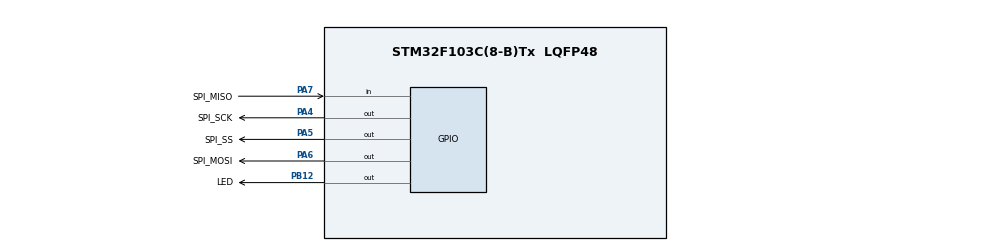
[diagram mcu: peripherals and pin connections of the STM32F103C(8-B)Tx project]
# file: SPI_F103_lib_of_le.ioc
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Mcu.Family=STM32F1
Mcu.Name=STM32F103C(8-B)Tx
Mcu.Package=LQFP48
NVIC.PriorityGroup=NVIC_PRIORITYGROUP_4
PA13.Mode=Serial_Wire
PA13.Signal=SYS_JTMS-SWDIO
PA14.Mode=Serial_Wire
PA14.Signal=SYS_JTCK-SWCLK
PA4.GPIO_Label=SPI_SCK
PA4.GPIO_Speed=GPIO_SPEED_FREQ_HIGH
PA4.Signal=GPIO_Output
PA5.GPIO_Label=SPI_SS
PA5.GPIO_Speed=GPIO_SPEED_FREQ_HIGH
PA5.Signal=GPIO_Output
PA6.GPIO_Label=SPI_MOSI
PA6.GPIO_Speed=GPIO_SPEED_FREQ_HIGH
PA6.Signal=GPIO_Output
PA7.GPIO_Label=SPI_MISO
PA7.Signal=GPIO_Input
PB12.GPIO_Label=LED
PB12.Signal=GPIO_Output
PD0-OSC_IN.Mode=HSE-External-Oscillator
PD0-OSC_IN.Signal=RCC_OSC_IN
PD1-OSC_OUT.Mode=HSE-External-Oscillator
PD1-OSC_OUT.Signal=RCC_OSC_OUT
ProjectManager.HeapSize=0x200
ProjectManager.StackSize=0x400
ProjectManager.TargetToolchain=STM32CubeIDE
RCC.APB1Freq_Value=8000000
RCC.APB2Freq_Value=8000000
RCC.SYSCLKSource=RCC_SYSCLKSOURCE_HSE
board=custom

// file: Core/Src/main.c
/* USER CODE BEGIN Header */
/**
  ******************************************************************************
  * @file           : main.c
  * @brief          : Main program body
  ******************************************************************************
  * @attention
  *
  * <h2><center>&copy; Copyright (c) 2020 STMicroelectronics.
  * All rights reserved.</center></h2>
  *
  * This software component is licensed by ST under BSD 3-Clause license,
  * the "License"; You may not use this file except in compliance with the
  * License. You may obtain a copy of the License at:
  *                        opensource.org/licenses/BSD-3-Clause
  *
  ******************************************************************************
  */
/* USER CODE END Header */
#include "main.h"

/* USER CODE BEGIN Includes */
#include "RF.h"
/* USER CODE END Includes */

void SystemClock_Config(void);
static void MX_GPIO_Init(void);

int main(void)
{

  /* MCU Configuration--------------------------------------------------------*/

  /* Reset of all peripherals, Initializes the Flash interface and the Systick. */
  HAL_Init();

  /* Configure the system clock */
  SystemClock_Config();

  /* Initialize all configured peripherals */
  MX_GPIO_Init();

  /* Infinite loop */
  /* USER CODE BEGIN WHILE */
  while (1)
  {
	  PrfWrRegPtr_U16(0x20, 0x2040);
	  HAL_GPIO_TogglePin(LED_GPIO_Port, LED_Pin);
	  HAL_Delay(200);
    /* USER CODE END WHILE */

  }
}

void SystemClock_Config(void)
{
  RCC_OscInitTypeDef RCC_OscInitStruct = {0};
  RCC_ClkInitTypeDef RCC_ClkInitStruct = {0};

  /** Initializes the RCC Oscillators according to the specified parameters
  * in the RCC_OscInitTypeDef structure.
  */
  RCC_OscInitStruct.OscillatorType = RCC_OSCILLATORTYPE_HSE;
  RCC_OscInitStruct.HSEState = RCC_HSE_ON;
  RCC_OscInitStruct.PLL.PLLState = RCC_PLL_NONE;
  if (HAL_RCC_OscConfig(&RCC_OscInitStruct) != HAL_OK)
  {
    Error_Handler();
  }
  /** Initializes the CPU, AHB and APB buses clocks
  */
  RCC_ClkInitStruct.ClockType = RCC_CLOCKTYPE_HCLK|RCC_CLOCKTYPE_SYSCLK
                              |RCC_CLOCKTYPE_PCLK1|RCC_CLOCKTYPE_PCLK2;
  RCC_ClkInitStruct.SYSCLKSource = RCC_SYSCLKSOURCE_HSE;
  RCC_ClkInitStruct.AHBCLKDivider = RCC_SYSCLK_DIV1;
  RCC_ClkInitStruct.APB1CLKDivider = RCC_HCLK_DIV1;
  RCC_ClkInitStruct.APB2CLKDivider = RCC_HCLK_DIV1;

  if (HAL_RCC_ClockConfig(&RCC_ClkInitStruct, FLASH_LATENCY_0) != HAL_OK)
  {
    Error_Handler();
  }
}

static void MX_GPIO_Init(void)
{
  GPIO_InitTypeDef GPIO_InitStruct = {0};

  /* GPIO Ports Clock Enable */
  __HAL_RCC_GPIOD_CLK_ENABLE();
  __HAL_RCC_GPIOA_CLK_ENABLE();
  __HAL_RCC_GPIOB_CLK_ENABLE();

  /*Configure GPIO pin Output Level */
  HAL_GPIO_WritePin(GPIOA, SPI_SCK_Pin|SPI_SS_Pin|SPI_MOSI_Pin, GPIO_PIN_RESET);

  /*Configure GPIO pin Output Level */
  HAL_GPIO_WritePin(LED_GPIO_Port, LED_Pin, GPIO_PIN_RESET);

  /*Configure GPIO pins : SPI_SCK_Pin SPI_SS_Pin SPI_MOSI_Pin */
  GPIO_InitStruct.Pin = SPI_SCK_Pin|SPI_SS_Pin|SPI_MOSI_Pin;
  GPIO_InitStruct.Mode = GPIO_MODE_OUTPUT_PP;
  GPIO_InitStruct.Pull = GPIO_NOPULL;
  GPIO_InitStruct.Speed = GPIO_SPEED_FREQ_HIGH;
  HAL_GPIO_Init(GPIOA, &GPIO_InitStruct);

  /*Configure GPIO pin : SPI_MISO_Pin */
  GPIO_InitStruct.Pin = SPI_MISO_Pin;
  GPIO_InitStruct.Mode = GPIO_MODE_INPUT;
  GPIO_InitStruct.Pull = GPIO_NOPULL;
  HAL_GPIO_Init(SPI_MISO_GPIO_Port, &GPIO_InitStruct);

  /*Configure GPIO pin : LED_Pin */
  GPIO_InitStruct.Pin = LED_Pin;
  GPIO_InitStruct.Mode = GPIO_MODE_OUTPUT_PP;
  GPIO_InitStruct.Pull = GPIO_NOPULL;
  GPIO_InitStruct.Speed = GPIO_SPEED_FREQ_LOW;
  HAL_GPIO_Init(LED_GPIO_Port, &GPIO_InitStruct);

}

void Error_Handler(void)
{
}

/************************ (C) COPYRIGHT STMicroelectronics *****END OF FILE****/
